VERSION ""

NS_ :

BS_:

BU_: VCU IMU DYN_F Volante DataLogger PDM DYN_R

BO_ 3221225472 VECTOR__INDEPENDENT_SIG_MSG: 0 Vector__XXX
 SG_ NewSignal_0011 : 16|8@1+ (1,0) [0|0] "" Vector__XXX
 SG_ NewSignal_0010 : 8|8@1+ (1,0) [0|0] "" Vector__XXX
 SG_ NewSignal_0012 : 24|8@1+ (1,0) [0|0] "" Vector__XXX
 SG_ NewSignal_0013 : 32|8@1+ (1,0) [0|0] "" Vector__XXX
 SG_ NewSignal_0014 : 40|8@1+ (1,0) [0|0] "" Vector__XXX
 SG_ NewSignal_0031 : 24|8@1+ (1,0) [0|0] "" Vector__XXX
 SG_ NewSignal_0052 : 56|8@1+ (1,0) [0|0] "" Vector__XXX
 SG_ DY_ST : 48|8@1+ (1,0) [0|1] "" Vector__XXX
 SG_ RL_PC : 40|8@1+ (1,0) [0|30] "" Vector__XXX
 SG_ RR_PC : 32|8@1+ (1,0) [0|30] "" Vector__XXX
 SG_ SusPos_RR : 24|8@1+ (1,0) [0|50] "mm" Vector__XXX
 SG_ SusPos_RL : 16|8@1+ (1,0) [0|50] "mm" Vector__XXX
 SG_ Wheel_Speed_RR : 8|8@1+ (1,0) [0|255] "km/h" Vector__XXX
 SG_ Wheel_Speed_RL : 0|8@1+ (1,0) [0|255] "km/h" Vector__XXX
 SG_ DY_ST : 48|8@1+ (1,0) [0|1] "" Vector__XXX
 SG_ FL_PC : 40|8@1+ (1,0) [0|30] "" Vector__XXX
 SG_ FR_PC : 32|8@1+ (1,0) [0|30] "" Vector__XXX
 SG_ SusPos_FR : 24|8@1+ (1,0) [0|50] "mm" Vector__XXX
 SG_ SusPos_FL : 16|8@1+ (1,0) [0|50] "mm" Vector__XXX
 SG_ Wheel_Speed_FR : 8|8@1+ (1,0) [0|255] "km/h" Vector__XXX
 SG_ Wheel_Speed_FL : 0|8@1+ (1,0) [0|255] "km/h" Vector__XXX

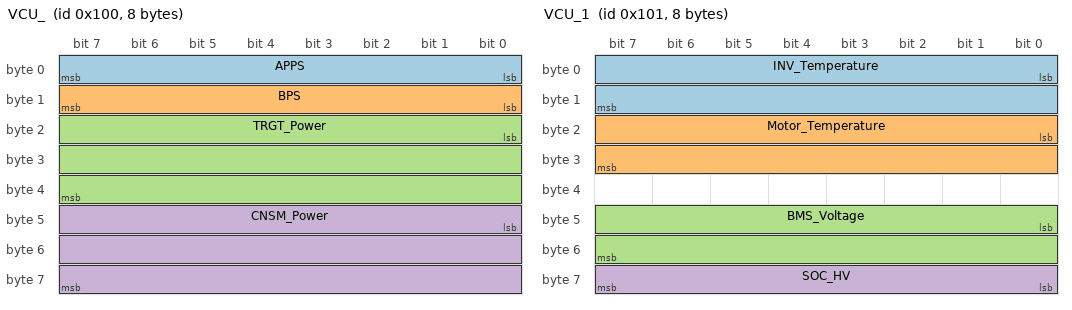
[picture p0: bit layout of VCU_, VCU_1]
BO_ 256 VCU_: 8 VCU
 SG_ APPS : 0|8@1+ (1,0) [0|100] "%" Vector__XXX
 SG_ BPS : 8|8@1+ (1,0) [0|0] "BAR" Vector__XXX
 SG_ TRGT_Power : 16|24@1+ (1,0) [0|85000] "W" Vector__XXX
 SG_ CNSM_Power : 40|24@1+ (1,0) [0|85000] "W" Vector__XXX

BO_ 257 VCU_1: 8 VCU
 SG_ INV_Temperature : 0|16@1+ (1,40) [0|300] "ï¿½C" Vector__XXX
 SG_ Motor_Temperature : 16|16@1+ (1,40) [0|100] "ï¿½C" Vector__XXX
 SG_ BMS_Voltage : 40|16@1+ (1,0) [0|0] "" Vector__XXX
 SG_ SOC_HV : 56|8@1+ (1,0) [0|0] "" Vector__XXX

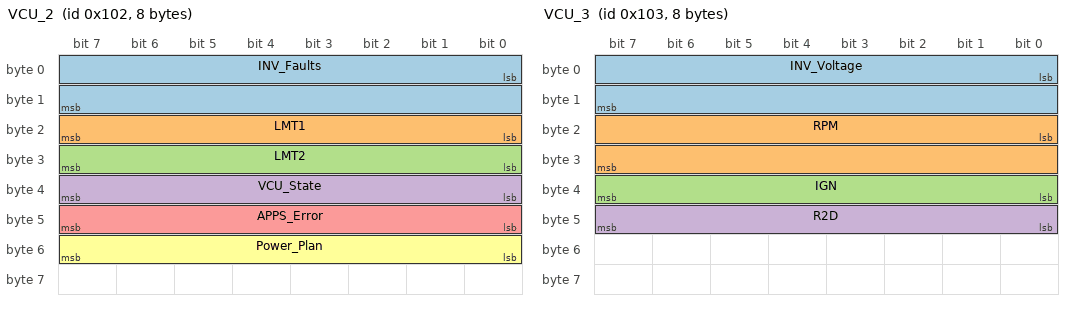
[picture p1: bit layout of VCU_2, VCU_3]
BO_ 258 VCU_2: 8 VCU
 SG_ INV_Faults : 0|16@1+ (1,0) [0|255] "" Vector__XXX
 SG_ LMT1 : 16|8@1+ (1,0) [0|1] "" Vector__XXX
 SG_ LMT2 : 24|8@1+ (1,0) [0|1] "" Vector__XXX
 SG_ VCU_State : 32|8@1+ (1,0) [0|1] "" Vector__XXX
 SG_ APPS_Error : 40|8@1+ (1,0) [0|1] "" Vector__XXX
 SG_ Power_Plan : 48|8@1+ (1,0) [0|5] "" Vector__XXX

BO_ 259 VCU_3: 8 VCU
 SG_ INV_Voltage : 0|16@1+ (1,0) [0|620] "V" Vector__XXX
 SG_ RPM : 16|16@1+ (1,0) [0|7000] "RPM" Vector__XXX
 SG_ IGN : 32|8@1+ (1,0) [0|1] "" Vector__XXX
 SG_ R2D : 40|8@1+ (1,0) [0|1] "" Vector__XXX

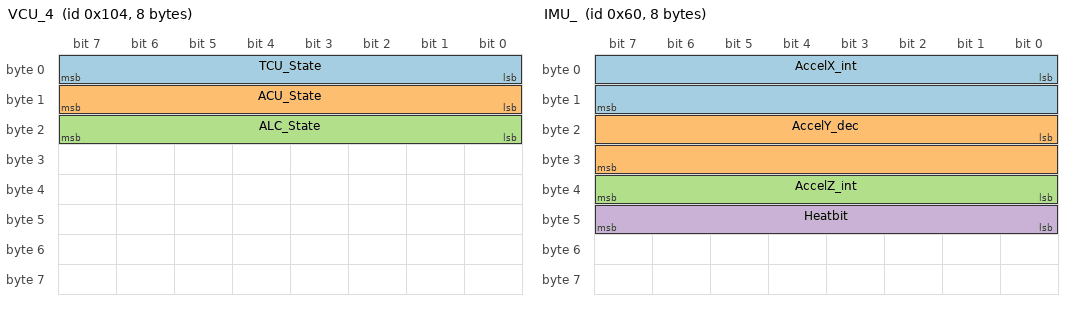
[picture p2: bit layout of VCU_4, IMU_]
BO_ 260 VCU_4: 8 VCU
 SG_ TCU_State : 0|8@1+ (1,0) [0|0] "" Vector__XXX
 SG_ ACU_State : 8|8@1+ (1,0) [0|0] "" Vector__XXX
 SG_ ALC_State : 16|8@1+ (1,0) [0|0] "" Vector__XXX

BO_ 96 IMU_: 8 IMU
 SG_ AccelX_int : 0|16@1+ (1,0) [0|0] "" Vector__XXX
 SG_ AccelY_dec : 16|16@1+ (1,0) [0|0] "" Vector__XXX
 SG_ AccelZ_int : 32|8@1+ (1,0) [0|0] "" Vector__XXX
 SG_ Heatbit : 40|8@1+ (1,0) [0|0] "" Vector__XXX

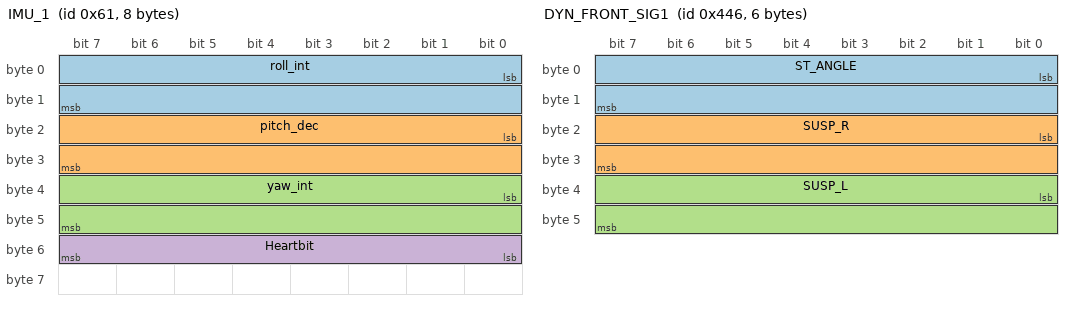
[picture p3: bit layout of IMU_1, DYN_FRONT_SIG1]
BO_ 97 IMU_1: 8 IMU
 SG_ roll_int : 0|16@1+ (1,0) [0|0] "" Vector__XXX
 SG_ pitch_dec : 16|16@1+ (1,0) [0|0] "" Vector__XXX
 SG_ yaw_int : 32|16@1+ (1,0) [0|0] "" Vector__XXX
 SG_ Heartbit : 48|8@1+ (1,0) [0|0] "" Vector__XXX

BO_ 1094 DYN_FRONT_SIG1: 6 DYN_F
 SG_ ST_ANGLE : 0|16@1- (0.1,0) [0|0] "º" Vector__XXX
 SG_ SUSP_R : 16|16@1+ (0.1,0) [0|0] "mm" Vector__XXX
 SG_ SUSP_L : 32|16@1+ (0.1,0) [0|0] "mm" Vector__XXX

BO_ 1110 DYN_FRONT_SIG2: 4 DYN_F
 SG_ SPD_LEFT : 0|16@1+ (0.1,0) [0|0] "km/h" Vector__XXX
 SG_ SPD_RIGHT : 16|16@1+ (0.1,0) [0|0] "km/h" Vector__XXX

BO_ 384 DataLogger: 8 DataLogger
 SG_ DL_state : 0|8@1+ (1,0) [0|1] "" Vector__XXX
 SG_ Recording_State : 8|8@1+ (1,0) [0|1] "" Vector__XXX

BO_ 261 VCU_5: 1 VCU
 SG_ brake_pressure_front : 0|8@1+ (0,0) [0|0] "Bar" Vector__XXX

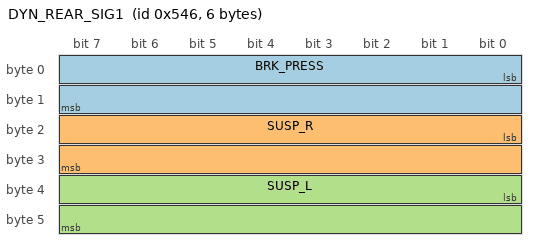
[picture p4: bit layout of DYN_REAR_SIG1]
BO_ 1350 DYN_REAR_SIG1: 6 DYN_R
 SG_ BRK_PRESS : 0|16@1+ (0.1,0) [0|0] "bar" Vector__XXX
 SG_ SUSP_R : 16|16@1+ (0.1,0) [0|0] "mm" Vector__XXX
 SG_ SUSP_L : 32|16@1+ (0.1,0) [0|0] "mm" Vector__XXX

BO_ 1366 DYN_REAR_SIG2: 4 DYN_R
 SG_ SPD_LEFT : 0|16@1+ (0.1,0) [0|0] "km/h" Vector__XXX
 SG_ SPD_RIGHT : 16|16@1+ (0.1,0) [0|0] "km/h" Vector__XXX

CM_ SG_ 3221225472 DY_ST "DY ST";
CM_ SG_ 3221225472 RL_PC "RL_Pulse_Count";
CM_ SG_ 3221225472 RR_PC "RR_Pulse_Count";
CM_ SG_ 3221225472 SusPos_RR "SusPos RR";
CM_ SG_ 3221225472 SusPos_RL "SusPos RL";
CM_ SG_ 3221225472 Wheel_Speed_RR "Wheel Speed RR";
CM_ SG_ 3221225472 Wheel_Speed_RL "Wheel Speed RL";
CM_ SG_ 3221225472 DY_ST "DY ST";
CM_ SG_ 3221225472 FL_PC "FL_Pulse_Count";
CM_ SG_ 3221225472 FR_PC "FR_Pulse_Count";
CM_ SG_ 3221225472 SusPos_FR "SusPos FR";
CM_ SG_ 3221225472 SusPos_FL "SusPos FL";
CM_ SG_ 3221225472 Wheel_Speed_FR "Wheel Speed FR";
CM_ SG_ 3221225472 Wheel_Speed_FL "Wheel Speed FL";
CM_ SG_ 256 APPS "Accelerator_Pedal_Position_Sense";
CM_ SG_ 256 BPS "Brake_Pressure";
CM_ SG_ 256 TRGT_Power "Target_Power";
CM_ SG_ 256 CNSM_Power "Current Consumed Power";
CM_ SG_ 257 INV_Temperature "Inverter_Temperature";
CM_ SG_ 257 Motor_Temperature "Motor_Temperature";
CM_ SG_ 257 BMS_Voltage "bms_voltage";
CM_ SG_ 257 SOC_HV "SOC_HV";
CM_ SG_ 258 INV_Faults "INVERSOR_ERROR";
CM_ SG_ 258 LMT1 "RPM_Power_Limit";
CM_ SG_ 258 LMT2 "Current_Limit_Motor_Temp";
CM_ SG_ 258 VCU_State "VCU_State";
CM_ SG_ 258 APPS_Error "APPS_Error";
CM_ SG_ 258 Power_Plan "Power_Plan_Switch_Volante";
CM_ SG_ 259 INV_Voltage "DC_Link_Inverter_Voltage";
CM_ SG_ 259 RPM "RPM";
CM_ SG_ 259 IGN "Ignition";
CM_ SG_ 259 R2D "Ready to drive";
CM_ SG_ 96 AccelX_int "X Acceleration Integer  (/100 para int,dec)";
CM_ SG_ 96 AccelY_dec "Y Acceleration Integer  (/100 para int,dec)";
CM_ SG_ 96 AccelZ_int "Z Acceleration Integer (/100 para int,dec)";
CM_ SG_ 96 Heatbit "Heartbit";
CM_ SG_ 97 roll_int "roll integer  (/100 para int,dec)";
CM_ SG_ 97 pitch_dec "pitch integer (/100 para int,dec)";
CM_ SG_ 97 yaw_int "yaw integer (/100 para int,dec)";
CM_ SG_ 97 Heartbit "Heartbit (/100 para int,dec)";
